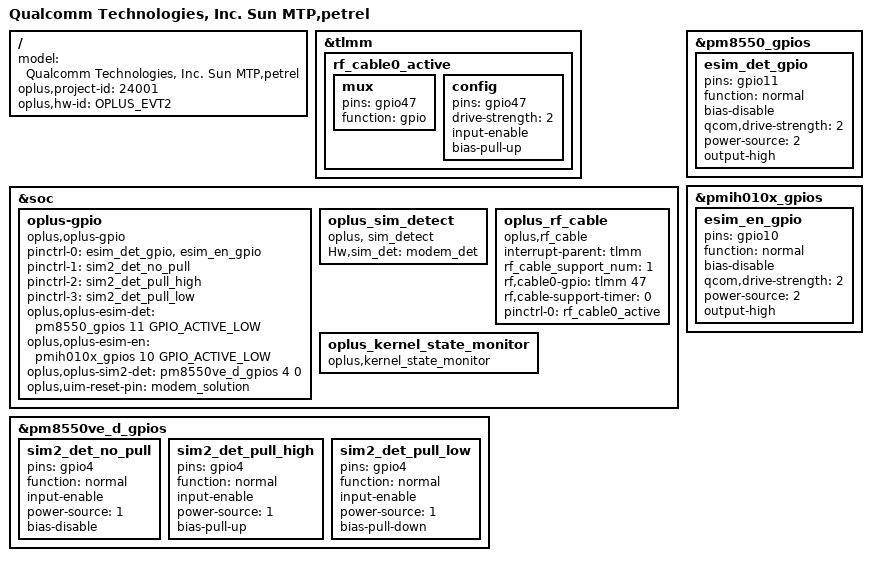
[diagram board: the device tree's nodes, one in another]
/dts-v1/;
/plugin/;
#include <dt-bindings/oplus/hw-id.h>
#include "../qcom/sun-mtp-v8-overlay.dts"
#include "sun_overlay_common.dtsi"
#include "oplus_nfc/petrel_nfc.dtsi"
#include "petrel_overlay_common.dtsi"
#include "oplus_misc/oplus-misc-24001.dtsi"
#include "oplus_chg/oplus-chg-24001.dtsi"
#include "oplus_chg/oplus-chg-24001-EVT2.dtsi"
#include "tp/petrel-oplus-tp-24001.dtsi"
#include "oplus_fp/oplus_fp_24001.dtsi"
#include "sensor/petrel-sensor-24001.dtsi"
#include <dt-bindings/regulator/qcom,rpmh-regulator-levels.h>

/ {
    model = "Qualcomm Technologies, Inc. Sun MTP,petrel";

    oplus,project-id = <24001>;
    oplus,hw-id = <OPLUS_EVT2>;
};

&tlmm {
  //#ifdef OPLUS_FEATURE_RF_CABLE_DETECT
  rf_cable0_active: rf_cable0_active {
      mux {
          pins = "gpio47";
          function = "gpio";
      };
      config {
          pins = "gpio47";
          drive-strength = <2>;
          input-enable;
          bias-pull-up;
      };
  };
  //#endif /* OPLUS_FEATURE_RF_CABLE_DETECT */
};

&soc {
  //#ifdef OPLUS_FEATURE_ESIM
  oplus-gpio {
    compatible = "oplus,oplus-gpio";
    pinctrl-names = "oplus_esim", "sim2_det_no_pull", "sim2_det_pull_high", "sim2_det_pull_low";
    pinctrl-0 = <&esim_det_gpio &esim_en_gpio>;
    pinctrl-1 = <&sim2_det_no_pull>;
    pinctrl-2 = <&sim2_det_pull_high>;
    pinctrl-3 = <&sim2_det_pull_low>;
    oplus,oplus-esim-det = <&pm8550_gpios 11 GPIO_ACTIVE_LOW>;
    oplus,oplus-esim-en = <&pmih010x_gpios 10 GPIO_ACTIVE_LOW>;
    oplus,oplus-sim2-det = <&pm8550ve_d_gpios 4 0>;
    oplus,uim-reset-pin = "modem_solution";
  };
  oplus_sim_detect {
    compatible = "oplus, sim_detect";
    Hw,sim_det = "modem_det";
  };
  //#endif /*OPLUS_FEATURE_ESIM*/
  //#ifdef OPLUS_FEATURE_RF_CABLE_DETECT
  oplus_rf_cable {
      compatible = "oplus,rf_cable";
      interrupt-parent = <&tlmm>;
      rf_cable_support_num = <1>;
      rf,cable0-gpio = <&tlmm 47 0>;
      rf,cable-support-timer = <0>;
      pinctrl-names = "rf_cable_active";
      pinctrl-0 = <&rf_cable0_active>;
  };
  //#endif /* OPLUS_FEATURE_RF_CABLE_DETECT */
};

&pm8550_gpios {
  esim_det_gpio: esim_det_gpio {
      pins = "gpio11";
      function = "normal";
      bias-disable; /* NO pull */
      qcom,drive-strength = <2>; /* 2 MA */
      power-source = <2>; /* 1.2V */
      output-high;
  };
};

&pmih010x_gpios {
  esim_en_gpio: esim_en_gpio {
      pins = "gpio10";
      function = "normal";
      bias-disable; /* NO pull */
      qcom,drive-strength = <2>; /* 2 MA */
      power-source = <2>; /* 1.2V */
      output-high;
  };
};

&pm8550ve_d_gpios {
    sim2_det_no_pull: sim2_det_no_pull {
        pins = "gpio4";
        function = "normal";
        input-enable;
        power-source = <1>;
        bias-disable;
    };

    sim2_det_pull_high: sim2_det_pull_high {
        pins = "gpio4";
        function = "normal";
        input-enable;
        power-source = <1>;
        bias-pull-up;
    };

    sim2_det_pull_low: sim2_det_pull_low {
        pins = "gpio4";
        function = "normal";
        input-enable;
        power-source = <1>;
        bias-pull-down;
    };
};

&soc {
  oplus_kernel_state_monitor {
    compatible = "oplus,kernel_state_monitor";
  };
};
